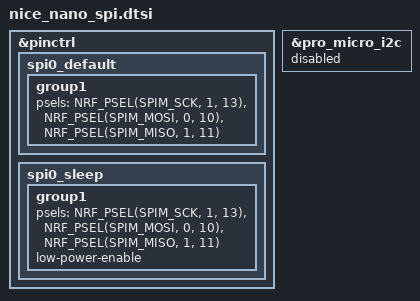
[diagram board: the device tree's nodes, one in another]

&pinctrl {
  spi0_default: spi0_default {
    group1 {
      psels = <NRF_PSEL(SPIM_SCK, 1, 13)>
            , <NRF_PSEL(SPIM_MOSI, 0, 10)>
            , <NRF_PSEL(SPIM_MISO, 1, 11)>
            ;
    };
  };

  spi0_sleep: spi0_sleep {
    group1 {
      psels = <NRF_PSEL(SPIM_SCK, 1, 13)>
            , <NRF_PSEL(SPIM_MOSI, 0, 10)>
            , <NRF_PSEL(SPIM_MISO, 1, 11)>
            ;
      low-power-enable;
    };
  };
};

&pro_micro_i2c {
  status = "disabled";
};
